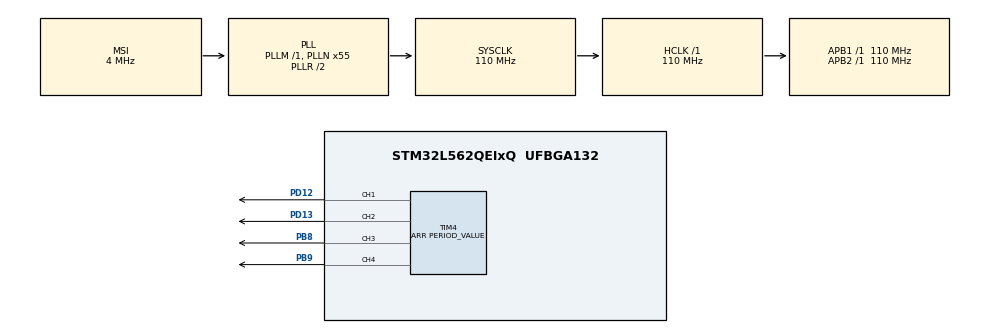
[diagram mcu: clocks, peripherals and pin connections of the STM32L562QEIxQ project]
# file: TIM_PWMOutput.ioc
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Mcu.Family=STM32L5
Mcu.Name=STM32L562QEIxQ
Mcu.Package=UFBGA132
NVIC.PriorityGroup=NVIC_PRIORITYGROUP_3
PB8.GPIO_PuPd=GPIO_PULLUP
PB8.GPIO_Speed=GPIO_SPEED_FREQ_VERY_HIGH
PB8.Signal=S_TIM4_CH3
PB9.GPIO_PuPd=GPIO_PULLUP
PB9.GPIO_Speed=GPIO_SPEED_FREQ_VERY_HIGH
PB9.Signal=S_TIM4_CH4
PD12.GPIO_PuPd=GPIO_PULLUP
PD12.GPIO_Speed=GPIO_SPEED_FREQ_VERY_HIGH
PD12.Signal=S_TIM4_CH1
PD13.GPIO_PuPd=GPIO_PULLUP
PD13.GPIO_Speed=GPIO_SPEED_FREQ_VERY_HIGH
PD13.Signal=S_TIM4_CH2
ProjectManager.HeapSize=0x200
ProjectManager.StackSize=0x400
ProjectManager.TargetToolchain=EWARM V8.32
RCC.AHBFreq_Value=110000000
RCC.APB1Freq_Value=110000000
RCC.APB1TimFreq_Value=110000000
RCC.APB2Freq_Value=110000000
RCC.APB2TimFreq_Value=110000000
RCC.CK48CLockSelection=RCC_USBCLKSOURCE_MSI
RCC.CortexFreq_Value=110000000
RCC.HCLKFreq_Value=110000000
RCC.HSE_VALUE=16000000
RCC.HSI48_VALUE=48000000
RCC.HSI_VALUE=16000000
RCC.LSE_VALUE=32768
RCC.MSI_VALUE=4000000
RCC.PLLN=55
RCC.SYSCLKFreq_VALUE=110000000
RCC.SYSCLKSource=RCC_SYSCLKSOURCE_PLLCLK
RCC.USBFreq_Value=4000000
RCC.VCOOutputFreq_Value=220000000
SH.S_TIM4_CH1.0=TIM4_CH1,PWM Generation1 CH1
SH.S_TIM4_CH2.0=TIM4_CH2,PWM Generation2 CH2
SH.S_TIM4_CH3.0=TIM4_CH3,PWM Generation3 CH3
SH.S_TIM4_CH4.0=TIM4_CH4,PWM Generation4 CH4
TIM4.AutoReloadPreload=TIM_AUTORELOAD_PRELOAD_DISABLE
TIM4.Channel-PWM\ Generation1\ CH1=TIM_CHANNEL_1
TIM4.Channel-PWM\ Generation2\ CH2=TIM_CHANNEL_2
TIM4.Channel-PWM\ Generation3\ CH3=TIM_CHANNEL_3
TIM4.Channel-PWM\ Generation4\ CH4=TIM_CHANNEL_4
TIM4.ClearInputSource=TIM_CLEARINPUTSOURCE_NONE
TIM4.ClockDivision=TIM_CLOCKDIVISION_DIV1
TIM4.CounterMode=TIM_COUNTERMODE_UP
TIM4.OC1Preload_PWM=ENABLE
TIM4.OC2Preload_PWM=ENABLE
TIM4.OC3Preload_PWM=ENABLE
TIM4.OC4Preload_PWM=ENABLE
TIM4.OCFastMode_PWM-PWM\ Generation1\ CH1=TIM_OCFAST_DISABLE
TIM4.OCFastMode_PWM-PWM\ Generation2\ CH2=TIM_OCFAST_DISABLE
TIM4.OCFastMode_PWM-PWM\ Generation3\ CH3=TIM_OCFAST_DISABLE
TIM4.OCFastMode_PWM-PWM\ Generation4\ CH4=TIM_OCFAST_DISABLE
TIM4.OCMode_PWM-PWM\ Generation1\ CH1=TIM_OCMODE_PWM1
TIM4.OCMode_PWM-PWM\ Generation2\ CH2=TIM_OCMODE_PWM1
TIM4.OCMode_PWM-PWM\ Generation3\ CH3=TIM_OCMODE_PWM1
TIM4.OCMode_PWM-PWM\ Generation4\ CH4=TIM_OCMODE_PWM1
TIM4.OCPolarity_1=TIM_OCPOLARITY_HIGH
TIM4.OCPolarity_2=TIM_OCPOLARITY_HIGH
TIM4.OCPolarity_3=TIM_OCPOLARITY_HIGH
TIM4.OCPolarity_4=TIM_OCPOLARITY_HIGH
TIM4.Period=PERIOD_VALUE
TIM4.Prescaler=PRESCALER_VALUE
TIM4.Pulse-PWM\ Generation1\ CH1=PULSE1_VALUE
TIM4.Pulse-PWM\ Generation2\ CH2=PULSE2_VALUE
TIM4.Pulse-PWM\ Generation3\ CH3=PULSE3_VALUE
TIM4.Pulse-PWM\ Generation4\ CH4=PULSE4_VALUE
TIM4.TIM_MasterOutputTrigger=TIM_TRGO_RESET
TIM4.TIM_MasterSlaveMode=TIM_MASTERSLAVEMODE_DISABLE
VP_ICACHE_VS_ICACHE.Mode=DirectMappedCache
VP_PWR_VS_DBSignals.Mode=DisableDeadBatterySignals
board=custom

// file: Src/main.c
/* USER CODE BEGIN Header */
/**
  ******************************************************************************
  * @file    TIM/TIM_PWMOutput/Src/main.c
  * @author  MCD Application Team
  * @brief   This sample code shows how to use STM32L5xx TIM HAL API to generate
  *          4 signals in PWM.
  ******************************************************************************
  * @attention
  *
  * Copyright (c) 2019 STMicroelectronics.
  * All rights reserved.
  *
  * This software is licensed under terms that can be found in the LICENSE file
  * in the root directory of this software component.
  * If no LICENSE file comes with this software, it is provided AS-IS.
  *
  ******************************************************************************
  */
/* USER CODE END Header */
#include "main.h"

TIM_HandleTypeDef htim4;

void SystemClock_Config(void);
static void MX_GPIO_Init(void);
static void MX_ICACHE_Init(void);
static void MX_TIM4_Init(void);

int main(void)
{
  /* USER CODE BEGIN 1 */

  /* STM32L5xx HAL library initialization:
       - Systick timer is configured by default as source of time base, but user
         can eventually implement his proper time base source (a general purpose
         timer for example or other time source), keeping in mind that Time base
         duration should be kept 1ms since PPP_TIMEOUT_VALUEs are defined and
         handled in milliseconds basis.
       - Set NVIC Group Priority to 3
       - Low Level Initialization
     */
  /* USER CODE END 1 */

  /* MCU Configuration--------------------------------------------------------*/

  /* Reset of all peripherals, Initializes the Flash interface and the Systick. */
  HAL_Init();

  /* Configure the system clock */
  SystemClock_Config();

  /* USER CODE BEGIN SysInit */

  /* Configure LED9 */
  BSP_LED_Init(LED9);

  /* USER CODE END SysInit */

  /* Initialize all configured peripherals */
  MX_GPIO_Init();
  MX_ICACHE_Init();
  MX_TIM4_Init();
  /* USER CODE BEGIN 2 */

/*## Start PWM signals generation #######################################*/
  /* Start channel 1 */
  if (HAL_TIM_PWM_Start(&htim4, TIM_CHANNEL_1) != HAL_OK)
  {
    /* PWM Generation Error */
    Error_Handler();
  }
  /* Start channel 2 */
  if (HAL_TIM_PWM_Start(&htim4, TIM_CHANNEL_2) != HAL_OK)
  {
    /* PWM Generation Error */
    Error_Handler();
  }
  /* Start channel 3 */
  if (HAL_TIM_PWM_Start(&htim4, TIM_CHANNEL_3) != HAL_OK)
  {
    /* PWM generation Error */
    Error_Handler();
  }
  /* Start channel 4 */
  if (HAL_TIM_PWM_Start(&htim4, TIM_CHANNEL_4) != HAL_OK)
  {
    /* PWM generation Error */
    Error_Handler();
  }

  /* USER CODE END 2 */

  /* Infinite loop */
  while (1)
  {

  }
}

void SystemClock_Config(void)
{
  RCC_OscInitTypeDef RCC_OscInitStruct = {0};
  RCC_ClkInitTypeDef RCC_ClkInitStruct = {0};

  /** Configure the main internal regulator output voltage
  */
  if (HAL_PWREx_ControlVoltageScaling(PWR_REGULATOR_VOLTAGE_SCALE0) != HAL_OK)
  {
    Error_Handler();
  }

  /** Initializes the RCC Oscillators according to the specified parameters
  * in the RCC_OscInitTypeDef structure.
  */
  RCC_OscInitStruct.OscillatorType = RCC_OSCILLATORTYPE_MSI;
  RCC_OscInitStruct.MSIState = RCC_MSI_ON;
  RCC_OscInitStruct.MSICalibrationValue = RCC_MSICALIBRATION_DEFAULT;
  RCC_OscInitStruct.MSIClockRange = RCC_MSIRANGE_6;
  RCC_OscInitStruct.PLL.PLLState = RCC_PLL_ON;
  RCC_OscInitStruct.PLL.PLLSource = RCC_PLLSOURCE_MSI;
  RCC_OscInitStruct.PLL.PLLM = 1;
  RCC_OscInitStruct.PLL.PLLN = 55;
  RCC_OscInitStruct.PLL.PLLP = RCC_PLLP_DIV7;
  RCC_OscInitStruct.PLL.PLLQ = RCC_PLLQ_DIV2;
  RCC_OscInitStruct.PLL.PLLR = RCC_PLLR_DIV2;
  if (HAL_RCC_OscConfig(&RCC_OscInitStruct) != HAL_OK)
  {
    Error_Handler();
  }

  /** Initializes the CPU, AHB and APB buses clocks
  */
  RCC_ClkInitStruct.ClockType = RCC_CLOCKTYPE_HCLK|RCC_CLOCKTYPE_SYSCLK
                              |RCC_CLOCKTYPE_PCLK1|RCC_CLOCKTYPE_PCLK2;
  RCC_ClkInitStruct.SYSCLKSource = RCC_SYSCLKSOURCE_PLLCLK;
  RCC_ClkInitStruct.AHBCLKDivider = RCC_SYSCLK_DIV1;
  RCC_ClkInitStruct.APB1CLKDivider = RCC_HCLK_DIV1;
  RCC_ClkInitStruct.APB2CLKDivider = RCC_HCLK_DIV1;

  if (HAL_RCC_ClockConfig(&RCC_ClkInitStruct, FLASH_LATENCY_5) != HAL_OK)
  {
    Error_Handler();
  }
}

static void MX_ICACHE_Init(void)
{

  /** Enable instruction cache in 1-way (direct mapped cache)
  */
  if (HAL_ICACHE_ConfigAssociativityMode(ICACHE_1WAY) != HAL_OK)
  {
    Error_Handler();
  }
  if (HAL_ICACHE_Enable() != HAL_OK)
  {
    Error_Handler();
  }

}

static void MX_TIM4_Init(void)
{

  TIM_MasterConfigTypeDef sMasterConfig = {0};
  TIM_OC_InitTypeDef sConfigOC = {0};

  htim4.Instance = TIM4;
  htim4.Init.Prescaler = PRESCALER_VALUE;
  htim4.Init.CounterMode = TIM_COUNTERMODE_UP;
  htim4.Init.Period = PERIOD_VALUE;
  htim4.Init.ClockDivision = TIM_CLOCKDIVISION_DIV1;
  htim4.Init.AutoReloadPreload = TIM_AUTORELOAD_PRELOAD_DISABLE;
  if (HAL_TIM_PWM_Init(&htim4) != HAL_OK)
  {
    Error_Handler();
  }
  sMasterConfig.MasterOutputTrigger = TIM_TRGO_RESET;
  sMasterConfig.MasterSlaveMode = TIM_MASTERSLAVEMODE_DISABLE;
  if (HAL_TIMEx_MasterConfigSynchronization(&htim4, &sMasterConfig) != HAL_OK)
  {
    Error_Handler();
  }
  sConfigOC.OCMode = TIM_OCMODE_PWM1;
  sConfigOC.Pulse = PULSE1_VALUE;
  sConfigOC.OCPolarity = TIM_OCPOLARITY_HIGH;
  sConfigOC.OCFastMode = TIM_OCFAST_DISABLE;
  if (HAL_TIM_PWM_ConfigChannel(&htim4, &sConfigOC, TIM_CHANNEL_1) != HAL_OK)
  {
    Error_Handler();
  }
  sConfigOC.Pulse = PULSE2_VALUE;
  if (HAL_TIM_PWM_ConfigChannel(&htim4, &sConfigOC, TIM_CHANNEL_2) != HAL_OK)
  {
    Error_Handler();
  }
  sConfigOC.Pulse = PULSE3_VALUE;
  if (HAL_TIM_PWM_ConfigChannel(&htim4, &sConfigOC, TIM_CHANNEL_3) != HAL_OK)
  {
    Error_Handler();
  }
  sConfigOC.Pulse = PULSE4_VALUE;
  if (HAL_TIM_PWM_ConfigChannel(&htim4, &sConfigOC, TIM_CHANNEL_4) != HAL_OK)
  {
    Error_Handler();
  }
  HAL_TIM_MspPostInit(&htim4);

}

static void MX_GPIO_Init(void)
{

  /* GPIO Ports Clock Enable */
  __HAL_RCC_GPIOB_CLK_ENABLE();
  __HAL_RCC_GPIOD_CLK_ENABLE();

}

void Error_Handler(void)
{
  /* USER CODE BEGIN Error_Handler_Debug */
  /* Turn LED9 on */
  BSP_LED_On(LED9);
  while(1)
  {
  }
  /* USER CODE END Error_Handler_Debug */
}
